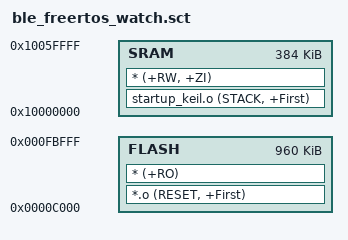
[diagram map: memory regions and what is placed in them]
;******************************************************************************
;
; ble_freertos_watch.sct
;
; Scatter file for Keil linker configuration.
;
;******************************************************************************

;******************************************************************************
;
; Copyright (c) 2020, Ambiq Micro
; All rights reserved.
;
; Redistribution and use in source and binary forms, with or without
; modification, are permitted provided that the following conditions are met:
;
; 1. Redistributions of source code must retain the above copyright notice,
; this list of conditions and the following disclaimer.
;
; 2. Redistributions in binary form must reproduce the above copyright
; notice, this list of conditions and the following disclaimer in the
; documentation and/or other materials provided with the distribution.
;
; 3. Neither the name of the copyright holder nor the names of its
; contributors may be used to endorse or promote products derived from this
; software without specific prior written permission.
;
; Third party software included in this distribution is subject to the
; additional license terms as defined in the /docs/licenses directory.
;
; THIS SOFTWARE IS PROVIDED BY THE COPYRIGHT HOLDERS AND CONTRIBUTORS "AS IS"
; AND ANY EXPRESS OR IMPLIED WARRANTIES, INCLUDING, BUT NOT LIMITED TO, THE
; IMPLIED WARRANTIES OF MERCHANTABILITY AND FITNESS FOR A PARTICULAR PURPOSE
; ARE DISCLAIMED. IN NO EVENT SHALL THE COPYRIGHT HOLDER OR CONTRIBUTORS BE
; LIABLE FOR ANY DIRECT, INDIRECT, INCIDENTAL, SPECIAL, EXEMPLARY, OR
; CONSEQUENTIAL DAMAGES (INCLUDING, BUT NOT LIMITED TO, PROCUREMENT OF
; SUBSTITUTE GOODS OR SERVICES; LOSS OF USE, DATA, OR PROFITS; OR BUSINESS
; INTERRUPTION) HOWEVER CAUSED AND ON ANY THEORY OF LIABILITY, WHETHER IN
; CONTRACT, STRICT LIABILITY, OR TORT (INCLUDING NEGLIGENCE OR OTHERWISE)
; ARISING IN ANY WAY OUT OF THE USE OF THIS SOFTWARE, EVEN IF ADVISED OF THE
; POSSIBILITY OF SUCH DAMAGE.
;
; This is part of revision 2.4.2 of the AmbiqSuite Development Package.
;
;******************************************************************************
LR_1 0x0000C000
{
    FLASH 0x0000C000 0x000F0000
    {
        *.o (RESET, +First)
        * (+RO)
    }

    SRAM 0x10000000 0x00060000
    {
        startup_keil.o (STACK, +First)
        * (+RW, +ZI)
    }
}

